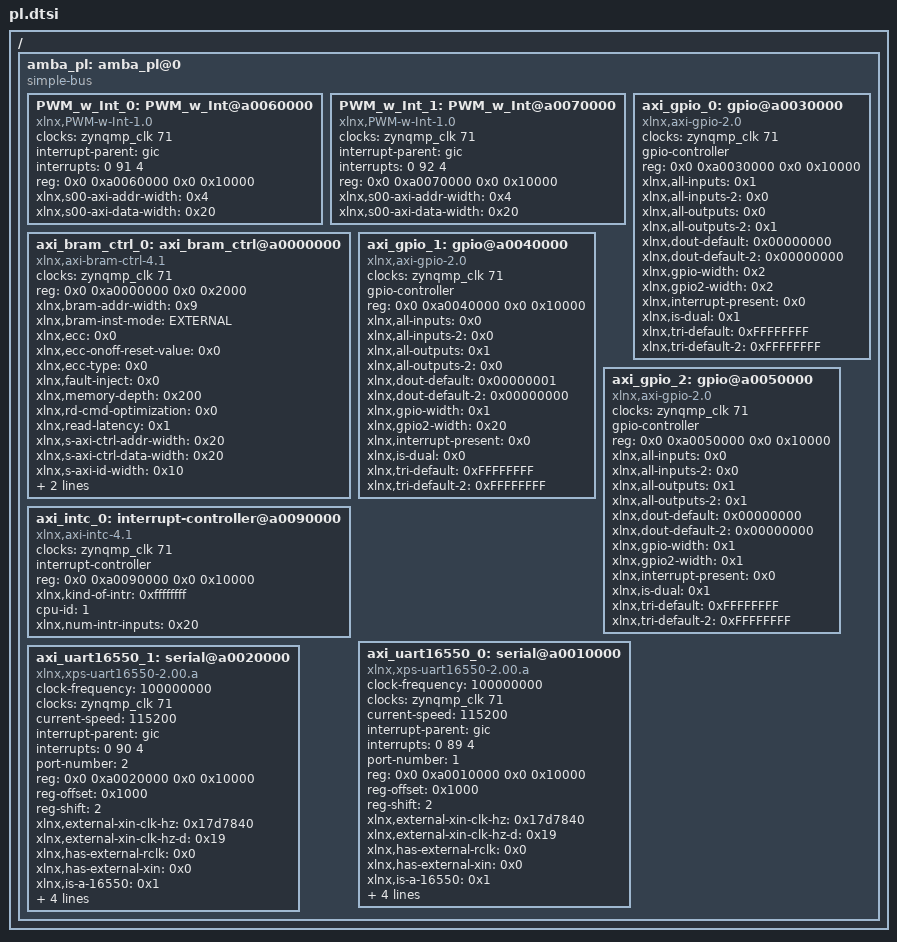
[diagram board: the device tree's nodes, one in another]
/*
 * CAUTION: This file is automatically generated by Xilinx.
 * Version:  
 * Today is: Wed Aug  5 20:56:51 2020
 */


/ {
	amba_pl: amba_pl@0 {
		#address-cells = <2>;
		#size-cells = <2>;
		compatible = "simple-bus";
		ranges ;
		PWM_w_Int_0: PWM_w_Int@a0060000 {
			clock-names = "s00_axi_aclk";
			clocks = <&zynqmp_clk 71>;
			compatible = "xlnx,PWM-w-Int-1.0";
			interrupt-names = "Interrupt_Out";
			interrupt-parent = <&gic>;
			interrupts = <0 91 4>;
			reg = <0x0 0xa0060000 0x0 0x10000>;
			xlnx,s00-axi-addr-width = <0x4>;
			xlnx,s00-axi-data-width = <0x20>;
		};
		PWM_w_Int_1: PWM_w_Int@a0070000 {
			clock-names = "s00_axi_aclk";
			clocks = <&zynqmp_clk 71>;
			compatible = "xlnx,PWM-w-Int-1.0";
			interrupt-names = "Interrupt_Out";
			interrupt-parent = <&gic>;
			interrupts = <0 92 4>;
			reg = <0x0 0xa0070000 0x0 0x10000>;
			xlnx,s00-axi-addr-width = <0x4>;
			xlnx,s00-axi-data-width = <0x20>;
		};
		axi_bram_ctrl_0: axi_bram_ctrl@a0000000 {
			clock-names = "s_axi_aclk";
			clocks = <&zynqmp_clk 71>;
			compatible = "xlnx,axi-bram-ctrl-4.1";
			reg = <0x0 0xa0000000 0x0 0x2000>;
			xlnx,bram-addr-width = <0x9>;
			xlnx,bram-inst-mode = "EXTERNAL";
			xlnx,ecc = <0x0>;
			xlnx,ecc-onoff-reset-value = <0x0>;
			xlnx,ecc-type = <0x0>;
			xlnx,fault-inject = <0x0>;
			xlnx,memory-depth = <0x200>;
			xlnx,rd-cmd-optimization = <0x0>;
			xlnx,read-latency = <0x1>;
			xlnx,s-axi-ctrl-addr-width = <0x20>;
			xlnx,s-axi-ctrl-data-width = <0x20>;
			xlnx,s-axi-id-width = <0x10>;
			xlnx,s-axi-supports-narrow-burst = <0x1>;
			xlnx,single-port-bram = <0x0>;
		};
		axi_gpio_0: gpio@a0030000 {
			#gpio-cells = <3>;
			clock-names = "s_axi_aclk";
			clocks = <&zynqmp_clk 71>;
			compatible = "xlnx,axi-gpio-2.0", "xlnx,xps-gpio-1.00.a";
			gpio-controller ;
			reg = <0x0 0xa0030000 0x0 0x10000>;
			xlnx,all-inputs = <0x1>;
			xlnx,all-inputs-2 = <0x0>;
			xlnx,all-outputs = <0x0>;
			xlnx,all-outputs-2 = <0x1>;
			xlnx,dout-default = <0x00000000>;
			xlnx,dout-default-2 = <0x00000000>;
			xlnx,gpio-width = <0x2>;
			xlnx,gpio2-width = <0x2>;
			xlnx,interrupt-present = <0x0>;
			xlnx,is-dual = <0x1>;
			xlnx,tri-default = <0xFFFFFFFF>;
			xlnx,tri-default-2 = <0xFFFFFFFF>;
		};
		axi_gpio_1: gpio@a0040000 {
			#gpio-cells = <3>;
			clock-names = "s_axi_aclk";
			clocks = <&zynqmp_clk 71>;
			compatible = "xlnx,axi-gpio-2.0", "xlnx,xps-gpio-1.00.a";
			gpio-controller ;
			reg = <0x0 0xa0040000 0x0 0x10000>;
			xlnx,all-inputs = <0x0>;
			xlnx,all-inputs-2 = <0x0>;
			xlnx,all-outputs = <0x1>;
			xlnx,all-outputs-2 = <0x0>;
			xlnx,dout-default = <0x00000001>;
			xlnx,dout-default-2 = <0x00000000>;
			xlnx,gpio-width = <0x1>;
			xlnx,gpio2-width = <0x20>;
			xlnx,interrupt-present = <0x0>;
			xlnx,is-dual = <0x0>;
			xlnx,tri-default = <0xFFFFFFFF>;
			xlnx,tri-default-2 = <0xFFFFFFFF>;
		};
		axi_gpio_2: gpio@a0050000 {
			#gpio-cells = <3>;
			clock-names = "s_axi_aclk";
			clocks = <&zynqmp_clk 71>;
			compatible = "xlnx,axi-gpio-2.0", "xlnx,xps-gpio-1.00.a";
			gpio-controller ;
			reg = <0x0 0xa0050000 0x0 0x10000>;
			xlnx,all-inputs = <0x0>;
			xlnx,all-inputs-2 = <0x0>;
			xlnx,all-outputs = <0x1>;
			xlnx,all-outputs-2 = <0x1>;
			xlnx,dout-default = <0x00000000>;
			xlnx,dout-default-2 = <0x00000000>;
			xlnx,gpio-width = <0x1>;
			xlnx,gpio2-width = <0x1>;
			xlnx,interrupt-present = <0x0>;
			xlnx,is-dual = <0x1>;
			xlnx,tri-default = <0xFFFFFFFF>;
			xlnx,tri-default-2 = <0xFFFFFFFF>;
		};
		axi_intc_0: interrupt-controller@a0090000 {
			#interrupt-cells = <2>;
			clock-names = "s_axi_aclk";
			clocks = <&zynqmp_clk 71>;
			compatible = "xlnx,axi-intc-4.1", "xlnx,xps-intc-1.00.a";
			interrupt-controller ;
			reg = <0x0 0xa0090000 0x0 0x10000>;
			xlnx,kind-of-intr = <0xffffffff>;
            cpu-id = <1>;
			xlnx,num-intr-inputs = <0x20>;
		};
		axi_uart16550_0: serial@a0010000 {
			clock-frequency = <100000000>;
			clock-names = "s_axi_aclk";
			clocks = <&zynqmp_clk 71>;
			compatible = "xlnx,xps-uart16550-2.00.a", "ns16550a";
			current-speed = <115200>;
			device_type = "serial";
			interrupt-names = "ip2intc_irpt";
			interrupt-parent = <&gic>;
			interrupts = <0 89 4>;
			port-number = <1>;
			reg = <0x0 0xa0010000 0x0 0x10000>;
			reg-offset = <0x1000>;
			reg-shift = <2>;
			xlnx,external-xin-clk-hz = <0x17d7840>;
			xlnx,external-xin-clk-hz-d = <0x19>;
			xlnx,has-external-rclk = <0x0>;
			xlnx,has-external-xin = <0x0>;
			xlnx,is-a-16550 = <0x1>;
			xlnx,s-axi-aclk-freq-hz-d = "100.0";
			xlnx,sim-device = "VERSAL_AI_CORE_ES1";
			xlnx,use-modem-ports = <0x1>;
			xlnx,use-user-ports = <0x1>;
		};
		axi_uart16550_1: serial@a0020000 {
			clock-frequency = <100000000>;
			clock-names = "s_axi_aclk";
			clocks = <&zynqmp_clk 71>;
			compatible = "xlnx,xps-uart16550-2.00.a", "ns16550a";
			current-speed = <115200>;
			device_type = "serial";
			interrupt-names = "ip2intc_irpt";
			interrupt-parent = <&gic>;
			interrupts = <0 90 4>;
			port-number = <2>;
			reg = <0x0 0xa0020000 0x0 0x10000>;
			reg-offset = <0x1000>;
			reg-shift = <2>;
			xlnx,external-xin-clk-hz = <0x17d7840>;
			xlnx,external-xin-clk-hz-d = <0x19>;
			xlnx,has-external-rclk = <0x0>;
			xlnx,has-external-xin = <0x0>;
			xlnx,is-a-16550 = <0x1>;
			xlnx,s-axi-aclk-freq-hz-d = "100.0";
			xlnx,sim-device = "VERSAL_AI_CORE_ES1";
			xlnx,use-modem-ports = <0x1>;
			xlnx,use-user-ports = <0x1>;
		};
	};
};
